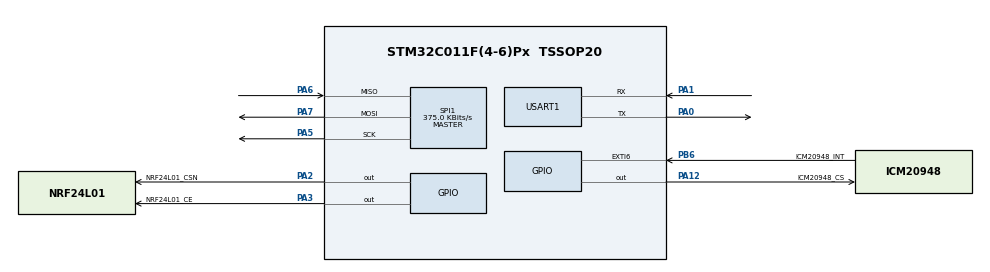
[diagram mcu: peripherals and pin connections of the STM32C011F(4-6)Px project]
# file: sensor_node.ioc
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Dma.Request0=SPI1_RX
Dma.Request1=SPI1_TX
Dma.Request2=USART1_TX
Dma.SPI1_RX.0.Direction=DMA_PERIPH_TO_MEMORY
Dma.SPI1_RX.0.EventEnable=DISABLE
Dma.SPI1_RX.0.Instance=DMA1_Channel1
Dma.SPI1_RX.0.MemDataAlignment=DMA_MDATAALIGN_BYTE
Dma.SPI1_RX.0.MemInc=DMA_MINC_ENABLE
Dma.SPI1_RX.0.Mode=DMA_NORMAL
Dma.SPI1_RX.0.PeriphDataAlignment=DMA_PDATAALIGN_BYTE
Dma.SPI1_RX.0.PeriphInc=DMA_PINC_DISABLE
Dma.SPI1_RX.0.Polarity=HAL_DMAMUX_REQ_GEN_RISING
Dma.SPI1_RX.0.Priority=DMA_PRIORITY_LOW
Dma.SPI1_RX.0.RequestNumber=1
Dma.SPI1_RX.0.SignalID=NONE
Dma.SPI1_RX.0.SyncEnable=DISABLE
Dma.SPI1_RX.0.SyncPolarity=HAL_DMAMUX_SYNC_NO_EVENT
Dma.SPI1_RX.0.SyncRequestNumber=1
Dma.SPI1_RX.0.SyncSignalID=NONE
Dma.SPI1_TX.1.Direction=DMA_MEMORY_TO_PERIPH
Dma.SPI1_TX.1.EventEnable=DISABLE
Dma.SPI1_TX.1.Instance=DMA1_Channel2
Dma.SPI1_TX.1.MemDataAlignment=DMA_MDATAALIGN_BYTE
Dma.SPI1_TX.1.MemInc=DMA_MINC_ENABLE
Dma.SPI1_TX.1.Mode=DMA_NORMAL
Dma.SPI1_TX.1.PeriphDataAlignment=DMA_PDATAALIGN_BYTE
Dma.SPI1_TX.1.PeriphInc=DMA_PINC_DISABLE
Dma.SPI1_TX.1.Polarity=HAL_DMAMUX_REQ_GEN_RISING
Dma.SPI1_TX.1.Priority=DMA_PRIORITY_LOW
Dma.SPI1_TX.1.RequestNumber=1
Dma.SPI1_TX.1.SignalID=NONE
Dma.SPI1_TX.1.SyncEnable=DISABLE
Dma.SPI1_TX.1.SyncPolarity=HAL_DMAMUX_SYNC_NO_EVENT
Dma.SPI1_TX.1.SyncRequestNumber=1
Dma.SPI1_TX.1.SyncSignalID=NONE
Dma.USART1_TX.2.Direction=DMA_MEMORY_TO_PERIPH
Dma.USART1_TX.2.EventEnable=DISABLE
Dma.USART1_TX.2.Instance=DMA1_Channel3
Dma.USART1_TX.2.MemDataAlignment=DMA_MDATAALIGN_BYTE
Dma.USART1_TX.2.MemInc=DMA_MINC_ENABLE
Dma.USART1_TX.2.Mode=DMA_NORMAL
Dma.USART1_TX.2.PeriphDataAlignment=DMA_PDATAALIGN_BYTE
Dma.USART1_TX.2.PeriphInc=DMA_PINC_DISABLE
Dma.USART1_TX.2.Polarity=HAL_DMAMUX_REQ_GEN_RISING
Dma.USART1_TX.2.Priority=DMA_PRIORITY_LOW
Dma.USART1_TX.2.RequestNumber=1
Dma.USART1_TX.2.SignalID=NONE
Dma.USART1_TX.2.SyncEnable=DISABLE
Dma.USART1_TX.2.SyncPolarity=HAL_DMAMUX_SYNC_NO_EVENT
Dma.USART1_TX.2.SyncRequestNumber=1
Dma.USART1_TX.2.SyncSignalID=NONE
Mcu.Family=STM32C0
Mcu.Name=STM32C011F(4-6)Px
Mcu.Package=TSSOP20
NVIC.DMA1_Channel1_IRQn=true\:0\:0\:false\:false\:true\:false\:true\:true
NVIC.DMA1_Channel2_3_IRQn=true\:0\:0\:false\:false\:true\:false\:true\:true
NVIC.EXTI4_15_IRQn=true\:0\:0\:false\:false\:true\:true\:true\:true
NVIC.SPI1_IRQn=true\:0\:0\:false\:false\:true\:true\:true\:true
NVIC.USART1_IRQn=true\:0\:0\:false\:false\:true\:true\:true\:true
PA0.Mode=Asynchronous
PA0.Signal=USART1_TX
PA1.Mode=Asynchronous
PA1.Signal=USART1_RX
PA12\ [PA10].GPIO_Label=ICM20948_CS
PA12\ [PA10].PinState=GPIO_PIN_SET
PA12\ [PA10].Signal=GPIO_Output
PA2.GPIO_Label=NRF24L01_CSN
PA2.PinState=GPIO_PIN_SET
PA2.Signal=GPIO_Output
PA3.GPIO_Label=NRF24L01_CE
PA3.Signal=GPIO_Output
PA5.Mode=Full_Duplex_Master
PA5.Signal=SPI1_SCK
PA6.Mode=Full_Duplex_Master
PA6.Signal=SPI1_MISO
PA7.Mode=Full_Duplex_Master
PA7.Signal=SPI1_MOSI
PB6.GPIO_Label=ICM20948_INT
PB6.GPIO_ModeDefaultEXTI=GPIO_MODE_IT_RISING
PB6.GPIO_PuPd=GPIO_NOPULL
PB6.Signal=GPXTI6
ProjectManager.HeapSize=0x200
ProjectManager.StackSize=0x400
ProjectManager.TargetToolchain=STM32CubeIDE
RCC.ADCFreq_Value=12000000
RCC.AHBFreq_Value=12000000
RCC.CortexFreq_Value=12000000
RCC.EXTERNAL_CLOCK_VALUE=12288000
RCC.HCLKFreq_Value=12000000
RCC.HSE_VALUE=8000000
RCC.HSI_VALUE=48000000
RCC.LSE_VALUE=32768
RCC.SYSCLKFreq_VALUE=12000000
SPI1.BaudRatePrescaler=SPI_BAUDRATEPRESCALER_32
SPI1.CalculateBaudRate=375.0 KBits/s
SPI1.Direction=SPI_DIRECTION_2LINES
SPI1.Mode=SPI_MODE_MASTER
SPI1.VirtualType=VM_MASTER
USART1.VirtualMode-Asynchronous=VM_ASYNC
board=custom

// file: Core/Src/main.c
/* USER CODE BEGIN Header */
/**
  ******************************************************************************
  * @file           : main.c
  * @brief          : Main program body
  ******************************************************************************
  * @attention
  *
  * Copyright (c) 2026 STMicroelectronics.
  * All rights reserved.
  *
  * This software is licensed under terms that can be found in the LICENSE file
  * in the root directory of this software component.
  * If no LICENSE file comes with this software, it is provided AS-IS.
  *
  ******************************************************************************
  */
/* USER CODE END Header */
#include "main.h"

SPI_HandleTypeDef hspi1;
DMA_HandleTypeDef hdma_spi1_rx;
DMA_HandleTypeDef hdma_spi1_tx;

UART_HandleTypeDef huart1;
DMA_HandleTypeDef hdma_usart1_tx;

void SystemClock_Config(void);
static void MX_GPIO_Init(void);
static void MX_DMA_Init(void);
static void MX_SPI1_Init(void);
static void MX_USART1_UART_Init(void);

int main(void)
{

  /* MCU Configuration--------------------------------------------------------*/

  /* Reset of all peripherals, Initializes the Flash interface and the Systick. */
  HAL_Init();

  /* Configure the system clock */
  SystemClock_Config();

  /* Initialize all configured peripherals */
  MX_GPIO_Init();
  MX_DMA_Init();
  MX_SPI1_Init();
  MX_USART1_UART_Init();
  /* USER CODE BEGIN 2 */
  cpp_main();
  /* USER CODE END 2 */

  /* Infinite loop */
  while (1)
  {

  }
}

void SystemClock_Config(void)
{
  RCC_OscInitTypeDef RCC_OscInitStruct = {0};
  RCC_ClkInitTypeDef RCC_ClkInitStruct = {0};

  __HAL_FLASH_SET_LATENCY(FLASH_LATENCY_0);

  /** Initializes the RCC Oscillators according to the specified parameters
  * in the RCC_OscInitTypeDef structure.
  */
  RCC_OscInitStruct.OscillatorType = RCC_OSCILLATORTYPE_HSI;
  RCC_OscInitStruct.HSIState = RCC_HSI_ON;
  RCC_OscInitStruct.HSIDiv = RCC_HSI_DIV4;
  RCC_OscInitStruct.HSICalibrationValue = RCC_HSICALIBRATION_DEFAULT;
  if (HAL_RCC_OscConfig(&RCC_OscInitStruct) != HAL_OK)
  {
    Error_Handler();
  }

  /** Initializes the CPU, AHB and APB buses clocks
  */
  RCC_ClkInitStruct.ClockType = RCC_CLOCKTYPE_HCLK|RCC_CLOCKTYPE_SYSCLK
                              |RCC_CLOCKTYPE_PCLK1;
  RCC_ClkInitStruct.SYSCLKSource = RCC_SYSCLKSOURCE_HSI;
  RCC_ClkInitStruct.SYSCLKDivider = RCC_SYSCLK_DIV1;
  RCC_ClkInitStruct.AHBCLKDivider = RCC_HCLK_DIV1;
  RCC_ClkInitStruct.APB1CLKDivider = RCC_APB1_DIV1;

  if (HAL_RCC_ClockConfig(&RCC_ClkInitStruct, FLASH_LATENCY_0) != HAL_OK)
  {
    Error_Handler();
  }
}

static void MX_SPI1_Init(void)
{

  /* SPI1 parameter configuration*/
  hspi1.Instance = SPI1;
  hspi1.Init.Mode = SPI_MODE_MASTER;
  hspi1.Init.Direction = SPI_DIRECTION_2LINES;
  hspi1.Init.DataSize = SPI_DATASIZE_8BIT;
  hspi1.Init.CLKPolarity = SPI_POLARITY_LOW;
  hspi1.Init.CLKPhase = SPI_PHASE_1EDGE;
  hspi1.Init.NSS = SPI_NSS_SOFT;
  hspi1.Init.BaudRatePrescaler = SPI_BAUDRATEPRESCALER_32;
  hspi1.Init.FirstBit = SPI_FIRSTBIT_MSB;
  hspi1.Init.TIMode = SPI_TIMODE_DISABLE;
  hspi1.Init.CRCCalculation = SPI_CRCCALCULATION_DISABLE;
  hspi1.Init.CRCPolynomial = 7;
  hspi1.Init.CRCLength = SPI_CRC_LENGTH_DATASIZE;
  hspi1.Init.NSSPMode = SPI_NSS_PULSE_ENABLE;
  if (HAL_SPI_Init(&hspi1) != HAL_OK)
  {
    Error_Handler();
  }

}

static void MX_USART1_UART_Init(void)
{

  huart1.Instance = USART1;
  huart1.Init.BaudRate = 115200;
  huart1.Init.WordLength = UART_WORDLENGTH_8B;
  huart1.Init.StopBits = UART_STOPBITS_1;
  huart1.Init.Parity = UART_PARITY_NONE;
  huart1.Init.Mode = UART_MODE_TX_RX;
  huart1.Init.HwFlowCtl = UART_HWCONTROL_NONE;
  huart1.Init.OverSampling = UART_OVERSAMPLING_16;
  huart1.Init.OneBitSampling = UART_ONE_BIT_SAMPLE_DISABLE;
  huart1.Init.ClockPrescaler = UART_PRESCALER_DIV1;
  huart1.AdvancedInit.AdvFeatureInit = UART_ADVFEATURE_NO_INIT;
  if (HAL_UART_Init(&huart1) != HAL_OK)
  {
    Error_Handler();
  }
  if (HAL_UARTEx_SetTxFifoThreshold(&huart1, UART_TXFIFO_THRESHOLD_1_8) != HAL_OK)
  {
    Error_Handler();
  }
  if (HAL_UARTEx_SetRxFifoThreshold(&huart1, UART_RXFIFO_THRESHOLD_1_8) != HAL_OK)
  {
    Error_Handler();
  }
  if (HAL_UARTEx_DisableFifoMode(&huart1) != HAL_OK)
  {
    Error_Handler();
  }

}

static void MX_DMA_Init(void)
{

  /* DMA controller clock enable */
  __HAL_RCC_DMA1_CLK_ENABLE();

  /* DMA interrupt init */
  /* DMA1_Channel1_IRQn interrupt configuration */
  HAL_NVIC_SetPriority(DMA1_Channel1_IRQn, 0, 0);
  HAL_NVIC_EnableIRQ(DMA1_Channel1_IRQn);
  /* DMA1_Channel2_3_IRQn interrupt configuration */
  HAL_NVIC_SetPriority(DMA1_Channel2_3_IRQn, 0, 0);
  HAL_NVIC_EnableIRQ(DMA1_Channel2_3_IRQn);

}

static void MX_GPIO_Init(void)
{
  GPIO_InitTypeDef GPIO_InitStruct = {0};

  /* GPIO Ports Clock Enable */
  __HAL_RCC_GPIOA_CLK_ENABLE();
  __HAL_RCC_GPIOB_CLK_ENABLE();

  /*Configure GPIO pin Output Level */
  HAL_GPIO_WritePin(GPIOA, NRF24L01_CSN_Pin|ICM20948_CS_Pin, GPIO_PIN_SET);

  /*Configure GPIO pin Output Level */
  HAL_GPIO_WritePin(NRF24L01_CE_GPIO_Port, NRF24L01_CE_Pin, GPIO_PIN_RESET);

  /*Configure GPIO pins : NRF24L01_CSN_Pin NRF24L01_CE_Pin ICM20948_CS_Pin */
  GPIO_InitStruct.Pin = NRF24L01_CSN_Pin|NRF24L01_CE_Pin|ICM20948_CS_Pin;
  GPIO_InitStruct.Mode = GPIO_MODE_OUTPUT_PP;
  GPIO_InitStruct.Pull = GPIO_NOPULL;
  GPIO_InitStruct.Speed = GPIO_SPEED_FREQ_LOW;
  HAL_GPIO_Init(GPIOA, &GPIO_InitStruct);

  /*Configure GPIO pin : ICM20948_INT_Pin */
  GPIO_InitStruct.Pin = ICM20948_INT_Pin;
  GPIO_InitStruct.Mode = GPIO_MODE_IT_RISING;
  GPIO_InitStruct.Pull = GPIO_NOPULL;
  HAL_GPIO_Init(ICM20948_INT_GPIO_Port, &GPIO_InitStruct);

  /* EXTI interrupt init*/
  HAL_NVIC_SetPriority(EXTI4_15_IRQn, 0, 0);
  HAL_NVIC_EnableIRQ(EXTI4_15_IRQn);

}

void Error_Handler(void)
{
  __disable_irq();
  while (1)
  {
  }
}
